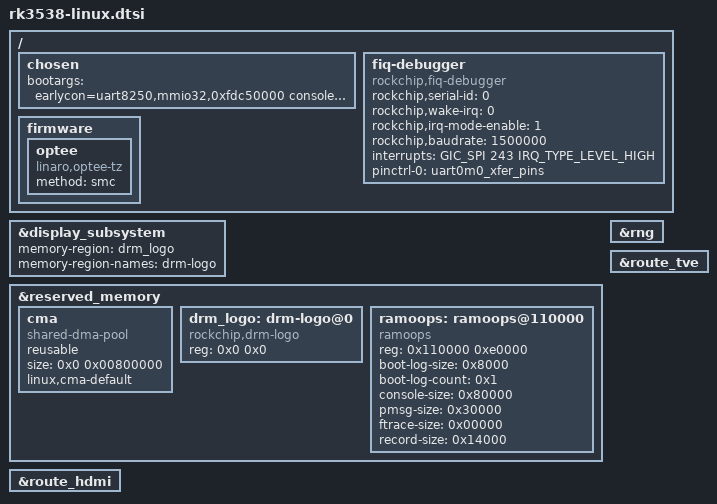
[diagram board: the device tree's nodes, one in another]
// SPDX-License-Identifier: (GPL-2.0+ OR MIT)
/*
 * Copyright (c) 2025 Rockchip Electronics Co., Ltd.
 *
 */

/ {
	chosen: chosen {
		bootargs = "earlycon=uart8250,mmio32,0xfdc50000 console=ttyFIQ0 root=PARTUUID=614e0000-0000 rw rootwait";
	};

	fiq-debugger {
		compatible = "rockchip,fiq-debugger";
		rockchip,serial-id = <0>;
		rockchip,wake-irq = <0>;
		/* If enable uart uses irq instead of fiq */
		rockchip,irq-mode-enable = <1>;
		rockchip,baudrate = <1500000>;  /* Only 115200 and 1500000 */
		interrupts = <GIC_SPI 243 IRQ_TYPE_LEVEL_HIGH>;
		pinctrl-names = "default";
		pinctrl-0 = <&uart0m0_xfer_pins>;
		status = "okay";
	};

	firmware {
		optee {
			compatible = "linaro,optee-tz";
			method = "smc";
		};
	};
};

&display_subsystem {
	memory-region = <&drm_logo>;
	memory-region-names = "drm-logo";
	/* devfreq = <&dmc>; */
};

&reserved_memory {
	cma {
		compatible = "shared-dma-pool";
		reusable;
		size = <0x0 0x00800000>;
		linux,cma-default;
	};

	drm_logo: drm-logo@0 {
		compatible = "rockchip,drm-logo";
		reg = <0x0 0x0>;
	};

	ramoops: ramoops@110000 {
		compatible = "ramoops";
		/* 0x110000 to 0x1f0000 is for ramoops */
		reg = <0x110000 0xe0000>;
		boot-log-size = <0x8000>;	/* do not change */
		boot-log-count = <0x1>;		/* do not change */
		console-size = <0x80000>;
		pmsg-size = <0x30000>;
		ftrace-size = <0x00000>;
		record-size = <0x14000>;
	};
};

&rng {
	status = "okay";
};

&route_hdmi {
	status = "okay";
};

&route_tve {
	status = "okay";
};

